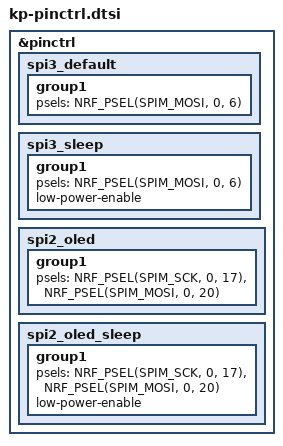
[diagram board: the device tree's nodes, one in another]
/*
 * Copyright (c) 2026 The ZMK Contributors
 * SPDX-License-Identifier: MIT
 */

&pinctrl {
    spi3_default: spi3_default {
        group1 {
            psels = <NRF_PSEL(SPIM_MOSI, 0, 6)>;
        };
    };

    spi3_sleep: spi3_sleep {
        group1 {
            psels = <NRF_PSEL(SPIM_MOSI, 0, 6)>;
            low-power-enable;
        };
    };

    spi2_oled: spi2_oled {
        group1 {
            psels = <NRF_PSEL(SPIM_SCK, 0, 17)>, <NRF_PSEL(SPIM_MOSI, 0, 20)>;
        };
    };

    spi2_oled_sleep: spi2_oled_sleep {
        group1 {
            psels = <NRF_PSEL(SPIM_SCK, 0, 17)>, <NRF_PSEL(SPIM_MOSI, 0, 20)>;
            low-power-enable;
        };
    };
};
